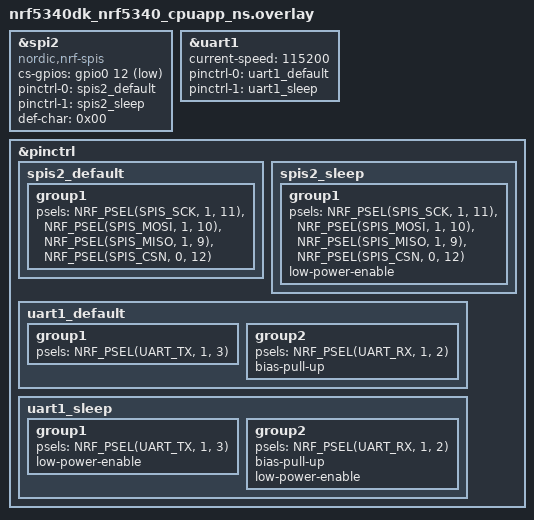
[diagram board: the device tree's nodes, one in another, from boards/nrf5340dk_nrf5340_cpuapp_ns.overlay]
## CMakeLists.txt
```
# SPDX-License-Identifier: Apache-2.0

cmake_minimum_required(VERSION 3.20.0)

# Ensure TFLM is visible to Zephyr even though it is not in west manifest.
set(EXTRA_ZEPHYR_MODULES
    $ENV{ZEPHYR_BASE}/modules/tflite-micro
)


find_package(Zephyr REQUIRED HINTS $ENV{ZEPHYR_BASE})
project(ecg_classifier)

# 添加源文件
target_sources(app PRIVATE
    src/main.c
    src/uart_sample_rx.c
    src/spi_comm.c
    src/ecg_buffer.c
    src/ecg_processing.c
    src/ble_output.c
)

if(NOT CONFIG_ECG_RAW_BLE_MODE)
    target_sources(app PRIVATE
        src/feature_extraction.c
        src/models/model_runtime.c
        src/models/model_backend_fnn_gboost_float.cc
        src/models/model_backend_fnn_float.cc
        src/models/model_backend_fnn_bagging_float.cc
        src/models/model_backend_fnn_gboost_int8.cc
        src/models/model_backend_fnn_bagging_int8.cc
        src/models/model_backend_fnn_int8.cc
        src/models/model_backend_binary_classic.c
        src/models/model_backend_binary_int8.c
        src/models/fnn_gboost_model_data.c
        src/models/fnn_float_model_data.c
        src/models/fnn_bagging_float_model_data.c
        src/models/fnn_gboost_int8_model_data.c
        src/models/fnn_int8_model_data.c
        src/models/fnn_bagging_int8_model_data.c
        fyp_integrate_int8/model_int8_params.c
        fyp_integrate_int8/utils_int8.c
        fyp_integrate/func.c
        fyp_integrate/model_globals.c
        fyp_integrate/1knn.c
        fyp_integrate/2dtree.c
        fyp_integrate/3svm.c
        fyp_integrate/4Bayes.c
        fyp_integrate/5lda.c
        fyp_integrate/7e_dtree.c
        fyp_integrate/8g_dtree.c
        fyp_integrate/11mix1.c
        fyp_integrate/12mix2.c
        fyp_integrate/13mix3.c
        src/online_moments.c
    )
endif()

# 添加头文件路径
target_include_directories(app PRIVATE include)
```

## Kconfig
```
#
# Application Kconfig
#

source "Kconfig.zephyr"

menu "ECG Application"

config ECG_RAW_BLE_MODE
	bool "Raw BLE passthrough mode"
	default n
	help
	  When enabled, all received ECG data is sent directly via BLE
	  without any feature extraction or model inference processing.
	  This is used for data collection and testing purposes.

config ECG_RAW_BLE_BASELINE
	bool "Raw BLE baseline power test mode"
	depends on ECG_RAW_BLE_MODE
	default n
	help
	  Enables baseline power test behavior for raw BLE mode:
	  - Keep UART print output enabled for controlled comparison
	  - Keep BLE send path active even when central is disconnected
	  This mode is intended only for power characterization.

endmenu
```

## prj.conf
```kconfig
# Copyright (c) 2018 Nordic Semiconductor
#
# SPDX-License-Identifier: LicenseRef-Nordic-5-Clause
#

# Enable the UART driver
CONFIG_UART_ASYNC_API=y
CONFIG_NRFX_UARTE0=y
CONFIG_NRFX_UARTE1=y
CONFIG_SERIAL=y

CONFIG_GPIO=y

# Make sure printk is printing to the UART console
CONFIG_CONSOLE=y
CONFIG_UART_CONSOLE=y

CONFIG_HEAP_MEM_POOL_SIZE=4096

CONFIG_BT=y
CONFIG_BT_PERIPHERAL=y
CONFIG_BT_DEVICE_NAME="Nordic_UART_Service"
CONFIG_BT_MAX_CONN=1
CONFIG_BT_MAX_PAIRED=1

# Enable the NUS service
CONFIG_BT_NUS=y

# Increase BLE throughput to support larger NUS packets
CONFIG_BT_L2CAP_TX_MTU=247
CONFIG_BT_BUF_ACL_TX_SIZE=251
CONFIG_BT_BUF_ACL_RX_SIZE=251
CONFIG_BT_CTLR_DATA_LENGTH_MAX=251

# Enable bonding
CONFIG_BT_SETTINGS=y
CONFIG_FLASH=y
CONFIG_FLASH_PAGE_LAYOUT=y
CONFIG_FLASH_MAP=y

# Enable DK LED and Buttons library
CONFIG_DK_LIBRARY=y

CONFIG_SYSTEM_WORKQUEUE_STACK_SIZE=4096
# Config logger
CONFIG_LOG=y
CONFIG_USE_SEGGER_RTT=y
CONFIG_LOG_BACKEND_RTT=y
CONFIG_LOG_BACKEND_UART=n
CONFIG_LOG_PRINTK=n

#Enable debugger
CONFIG_DEBUG_OPTIMIZATIONS=y
CONFIG_ASSERT=y
CONFIG_DEBUG_INFO=y
CONFIG_DEBUG_THREAD_INFO=y

# SPI configuration
CONFIG_SPI=y
CONFIG_SPI_SLAVE=y
CONFIG_SPI_LOG_LEVEL_INF=y
CONFIG_SPI_ASYNC=y

# Memory configuration
CONFIG_HEAP_MEM_POOL_SIZE=8192
CONFIG_MAIN_STACK_SIZE=4096

# Math library support
CONFIG_NEWLIB_LIBC=y
CONFIG_CPP=y
CONFIG_STD_CPP17=y
CONFIG_TENSORFLOW_LITE_MICRO=y

# printk float support
CONFIG_CBPRINTF_COMPLETE=y
CONFIG_CBPRINTF_FP_SUPPORT=y
# CONFIG_NEWLIB_LIBC_FLOAT_PRINTF=y
# CONFIG_NEWLIB_LIBC_FLOAT_SCANF=y
CONFIG_FPU=y

# Enable floating point support
# CONFIG_CBPRINTF_FP_SUPPORT=y
```

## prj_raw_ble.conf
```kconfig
#
# prj_raw_ble.conf - Raw BLE passthrough mode
# 所有ECG数据直接通过BLE转发，不做特征提取和推理
# 关闭所有串口打印，最大化BLE吞吐
#

# Enable raw BLE passthrough mode
CONFIG_ECG_RAW_BLE_MODE=y
CONFIG_ECG_RAW_BLE_BASELINE=y

# UART driver (for ECG data reception only)
CONFIG_UART_ASYNC_API=y
CONFIG_NRFX_UARTE0=y
CONFIG_NRFX_UARTE1=y
CONFIG_SERIAL=y

CONFIG_GPIO=y

# Enable UART console/printk output (match normal test visibility)
CONFIG_CONSOLE=y
CONFIG_UART_CONSOLE=y
CONFIG_PRINTK=y

# Enable logging on UART for baseline comparison
CONFIG_LOG=y
CONFIG_USE_SEGGER_RTT=n
CONFIG_LOG_BACKEND_RTT=n
CONFIG_LOG_BACKEND_UART=y
CONFIG_LOG_PRINTK=n

# Keep debug/assert aligned with normal logic test style
CONFIG_ASSERT=y
CONFIG_DEBUG_OPTIMIZATIONS=y
CONFIG_DEBUG_INFO=y
CONFIG_DEBUG_THREAD_INFO=y

# BLE configuration
CONFIG_BT=y
CONFIG_BT_PERIPHERAL=y
CONFIG_BT_DEVICE_NAME="Nordic_UART_Service"
CONFIG_BT_MAX_CONN=1
CONFIG_BT_MAX_PAIRED=1

CONFIG_BT_NUS=y

# Throughput settings (match normal mode)
CONFIG_BT_L2CAP_TX_MTU=247
CONFIG_BT_BUF_ACL_TX_SIZE=251
CONFIG_BT_BUF_ACL_RX_SIZE=251
CONFIG_BT_CTLR_DATA_LENGTH_MAX=251
CONFIG_BT_CONN_TX_MAX=10

# Prefer shorter connection interval for faster NUS notifications
CONFIG_BT_GAP_AUTO_UPDATE_CONN_PARAMS=y
CONFIG_BT_PERIPHERAL_PREF_MIN_INT=6
CONFIG_BT_PERIPHERAL_PREF_MAX_INT=12
CONFIG_BT_PERIPHERAL_PREF_LATENCY=0
CONFIG_BT_PERIPHERAL_PREF_TIMEOUT=400

CONFIG_BT_SETTINGS=y
CONFIG_FLASH=y
CONFIG_FLASH_PAGE_LAYOUT=y
CONFIG_FLASH_MAP=y

CONFIG_DK_LIBRARY=y

CONFIG_HEAP_MEM_POOL_SIZE=8192
CONFIG_MAIN_STACK_SIZE=4096
CONFIG_SYSTEM_WORKQUEUE_STACK_SIZE=4096

# SPI configuration
CONFIG_SPI=y
CONFIG_SPI_SLAVE=y
CONFIG_SPI_ASYNC=y

# Math/libc (still needed for memcpy etc.)
CONFIG_NEWLIB_LIBC=y
CONFIG_FPU=y

# No C++ / TFLM needed in raw mode
CONFIG_CPP=n
```

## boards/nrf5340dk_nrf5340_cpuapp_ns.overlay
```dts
// To get started, press Ctrl+Space to bring up the completion menu and view the available nodes.

// You can also use the buttons in the sidebar to perform actions on nodes.
// Actions currently available include:

// * Enabling / disabling the node
// * Adding the bus to a bus
// * Removing the node
// * Connecting ADC channels

// For more help, browse the DeviceTree documentation at https://docs.zephyrproject.org/latest/guides/dts/index.html
// You can also visit the nRF DeviceTree extension documentation at https://docs.nordicsemi.com/bundle/nrf-connect-vscode/page/guides/ncs_configure_app.html#devicetree-support-in-the-extension
/* Enable SPIS1 on nRF5340 DK */
&spi2 {
    compatible = "nordic,nrf-spis";   /* 改为从机模式 */
    status = "okay";

    /* CS = P0.12 (Active-low) */
    cs-gpios = <&gpio0 12 GPIO_ACTIVE_LOW>;

    pinctrl-0 = <&spis2_default>;
    pinctrl-1 = <&spis2_sleep>;
    pinctrl-names = "default", "sleep";
    def-char = < 0x00 >; /* SPIS 从机默认返回字符 */
};

&uart1 {
    status = "okay";
    current-speed = <115200>;
    pinctrl-0 = <&uart1_default>;
    pinctrl-1 = <&uart1_sleep>;
    pinctrl-names = "default", "sleep";
};

/* Pin control config */
&pinctrl {
    spis2_default: spis2_default {
        group1 {
            psels = 
                <NRF_PSEL(SPIS_SCK,  1, 11)>,   /* SCK  P1.11 */
                <NRF_PSEL(SPIS_MOSI, 1, 10)>,   /* MOSI P1.10 */
                <NRF_PSEL(SPIS_MISO, 1, 9)>,   /* MISO P1.09 */
                <NRF_PSEL(SPIS_CSN,  0, 12)>;  /* ★ 关键：CS */
        };
    };

    spis2_sleep: spis2_sleep {
        group1 {
            psels = 
                <NRF_PSEL(SPIS_SCK,  1, 11)>,   /* SCK  P1.11 */
                <NRF_PSEL(SPIS_MOSI, 1, 10)>,   /* MOSI P1.10 */
                <NRF_PSEL(SPIS_MISO, 1, 9)>,   /* MISO P1.09 */
                <NRF_PSEL(SPIS_CSN,  0, 12)>;  /* ★ 关键：CS */
            low-power-enable;
        };
    };

    uart1_default: uart1_default {
        group1 {
            psels = <NRF_PSEL(UART_TX, 1, 3)>;
        };

        group2 {
            psels = <NRF_PSEL(UART_RX, 1, 2)>;
            bias-pull-up;
        };
    };

    uart1_sleep: uart1_sleep {
        group1 {
            psels = <NRF_PSEL(UART_TX, 1, 3)>;
            low-power-enable;
        };

        group2 {
            psels = <NRF_PSEL(UART_RX, 1, 2)>;
            bias-pull-up;
            low-power-enable;
        };
    };
};
```

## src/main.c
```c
/**
 * @file main.c
 * @brief NRF5340 ECG应用主程序
 * 
 * 架构（异步快照版）：
 * UART ISR → ECG缓冲队列 → 主循环收集样本 → 快照 → k_work工作线程处理
 *   主循环：只负责收集，不做耗时计算，收满即快照+提交work+立即继续
 *   工作线程：process_window + 特征提取 + 模型推理 + (未来)BLE发送
 */

#include <zephyr/kernel.h>
#include <zephyr/logging/log.h>
#include <zephyr/sys/printk.h>
#include <errno.h>
#include <string.h>

#include "uart_sample_rx.h"
#include "ecg_buffer.h"
#include "ecg_processing.h"
#include "ble_output.h"

#if !IS_ENABLED(CONFIG_ECG_RAW_BLE_MODE)
#include "feature_extraction.h"
#include "models/model_runtime.h"
#endif

LOG_MODULE_REGISTER(app, LOG_LEVEL_INF);

/* ===== 配置常量 ===== */
#define ECG_FS              300
#define WINDOW_SEC          30
#define ECG_BUFFER_SIZE     200   /* 扩大缓冲区，覆盖快照memcpy期间ISR写入 */
#define BLE_QUEUE_SIZE      10
#define ENABLE_BLE_OUTPUT   0

/* ===== 主循环收集用对象 ===== */
static ecg_buffer_t ecg_buffer;

#if IS_ENABLED(CONFIG_ECG_RAW_BLE_MODE)
/* ===== Raw BLE passthrough: 仅需一个样本缓冲区 ===== */
static int16_t raw_buffer[BLE_OUTPUT_MAX_WINDOW_SAMPLES];
static uint32_t raw_buffer_pos;
static uint32_t raw_target_samples;
static uint32_t raw_windows_collected;
static uint32_t raw_windows_submitted;
static uint32_t raw_windows_skipped;

#else /* Normal processing mode */

/* 当前默认模型 */
#define ACTIVE_MODEL        ECG_MODEL_BIN_I8_SVM

static window_manager_t window_mgr;
static feature_extraction_t feature_eng;
static ecg_model_runtime_t model_runtime;

/* ===== 快照区：主循环写入，工作线程读取，信号量保护 ===== */
static feature_extraction_t snap_feature_eng;
static window_integrity_t   snap_integrity;
static uint16_t             snap_file_id;
static K_SEM_DEFINE(snap_sem, 1, 1);  /* 1=快照区空闲, 0=工作线程占用 */

/* ===== 工作队列 ===== */
static struct k_work process_work;
static uint32_t snap_timestamp_ms;     /* 快照时刻 */
static uint32_t windows_collected;     /* 主循环已收集窗口计数 */
static uint32_t windows_processed;     /* 工作线程已处理窗口计数 */
static uint32_t windows_skipped;       /* 快照区忙导致跳过的窗口计数 */

/**
 * @brief 工作线程处理函数
 * 
 * 在系统工作队列线程中执行，不阻塞主循环。
 * 流程：process_window → 特征提取 → 模型推理 → 打印结果 → 释放快照区  
 */
static void process_work_handler(struct k_work *work)
{
    ARG_UNUSED(work);

    uint32_t work_t0 = k_uptime_get_32();

    printk("\n[WORK] === Processing snapshot file=%u (collected=%u) ===\n",
           snap_file_id, windows_collected);

    /* 1) 执行 process_window（耗时 ~154ms） */
    uint32_t pw_t0 = k_uptime_get_32();
    process_window(&snap_feature_eng);
    uint32_t pw_t1 = k_uptime_get_32();
    snap_feature_eng.last_extract_time_ms = (pw_t1 - pw_t0);

    if (!snap_feature_eng.ready) {
        printk("[WORK] process_window failed for file=%u\n", snap_file_id);
        windows_processed++;
        k_sem_give(&snap_sem);
        return;
    }

    /* 2) 提取特征 */
    double features[6];
    feature_extraction_get(features, &snap_feature_eng);

    printk("[WORK] Feature extraction time: %u ms\n", snap_feature_eng.last_extract_time_ms);
    printk("[WORK] Window integrity: %u%% (%u/%u samples)\n",
           snap_integrity.integrity_percent,
           snap_integrity.received_samples,
           snap_integrity.expected_samples);
    printk("[WORK] Kurtosis: [%.4f, %.4f, %.4f]\n",
           features[0], features[1], features[2]);
    printk("[WORK] Skewness: [%.4f, %.4f, %.4f]\n",
           features[3], features[4], features[5]);

    /* 3) 模型推理 */
    ecg_model_result_t infer_out = {0};
    uint32_t inf_t0 = k_uptime_get_32();
    int ret = ecg_model_runtime_infer(&model_runtime, features, &infer_out);
    uint32_t inf_t1 = k_uptime_get_32();

    printk("[WORK] Inference time: %u ms\n", (inf_t1 - inf_t0));

    if (ret == 0) {
        printk("[WORK] Inference: model=%s label=%d score=%.5f\n",
               ecg_model_runtime_name(model_runtime.active_model),
               infer_out.label, (double)infer_out.score);
    } else {
        printk("[WORK] Inference failed: %d\n", ret);
    }

    /* 4) 结果判断 + 备份数据可用性验证 */
    if (ret == 0 && snap_integrity.is_valid && infer_out.label == 1) {
        printk("[WORK] >>> VALID: file=%u label=1, backup %u samples ready for BLE <<<\n",
               snap_file_id, snap_feature_eng.buffer_pos);

#if ENABLE_BLE_OUTPUT
        int ble_ret = ble_output_submit_window(
            snap_file_id,
            snap_feature_eng.buffer,
            snap_feature_eng.buffer_pos,
            ECG_FS,
            (uint8_t)snap_integrity.integrity_percent,
            infer_out.label
        );

        if (ble_ret == 0) {
            printk("[WORK] BLE submit OK: file=%u samples=%u connected=%d\n",
                   snap_file_id,
                   snap_feature_eng.buffer_pos,
                   ble_output_is_connected() ? 1 : 0);
        } else if (ble_ret == -EBUSY) {
            printk("[WORK] BLE submit BUSY: previous window still sending, file=%u skipped\n",
                   snap_file_id);
        } else {
            printk("[WORK] BLE submit failed: %d (file=%u)\n", ble_ret, snap_file_id);
        }
#endif
    } else {
        printk("[WORK] Window not sent: integrity=%u%% label=%d ret=%d\n",
               snap_integrity.integrity_percent,
               (ret == 0) ? infer_out.label : -1, ret);
    }

    uint32_t work_t1 = k_uptime_get_32();
    printk("[WORK] Total work time: %u ms (snap_delay=%u ms)\n",
           (work_t1 - work_t0), (work_t0 - snap_timestamp_ms));

    windows_processed++;
    printk("[WORK] Stats: collected=%u processed=%u skipped=%u\n",
           windows_collected, windows_processed, windows_skipped);

    /* 5) 释放快照区，主循环可以写入下一个快照 */
    k_sem_give(&snap_sem);
}

#endif /* !CONFIG_ECG_RAW_BLE_MODE */

/**
 * @brief 主程序
 */
int main(void)
{
    printk("=== NRF5340 ECG Application Start ===\n");

    int ret = ecg_buffer_init(&ecg_buffer, ECG_BUFFER_SIZE);
    if (ret != 0) {
        printk("Failed to init ECG buffer: %d\n", ret);
        return ret;
    }

    ret = uart_sample_rx_init_async(&ecg_buffer);
    if (ret != 0) {
        printk("Failed to init UART RX: %d\n", ret);
        return ret;
    }

#if IS_ENABLED(CONFIG_ECG_RAW_BLE_MODE)
    /* ===== Raw BLE passthrough mode ===== */
    printk("Mode: RAW BLE PASSTHROUGH (no processing)\n");

    ret = ble_output_init(BLE_QUEUE_SIZE);
    if (ret != 0) {
        printk("Failed to init BLE output: %d\n", ret);
        return ret;
    }

    ret = ble_output_start();
    if (ret != 0) {
        printk("Failed to start BLE stack: %d\n", ret);
        return ret;
    }

    printk("BLE ready, waiting for connection...\n");

    raw_windows_collected = 0;
    raw_windows_submitted = 0;
    raw_windows_skipped = 0;

    ecg_sample_t sample;
    bool window_active = false;
    uint16_t current_file_id = 0;

    while (1) {
        uart_window_header_t header;
        if (uart_sample_rx_try_get_window_header(&header)) {
            if (window_active) {
                printk("[RAW] Header file=%u IGNORED (busy file=%u)\n",
                       header.file_id, current_file_id);
            } else {
                if (header.sample_count == 0 ||
                    header.sample_count > BLE_OUTPUT_MAX_WINDOW_SAMPLES) {
                    printk("[RAW] Invalid sample count: %u\n", header.sample_count);
                    continue;
                }
                raw_target_samples = header.sample_count;
                raw_buffer_pos = 0;
                current_file_id = header.file_id;
                window_active = true;
                printk("[RAW] Header file=%u samples=%u\n",
                       header.file_id, header.sample_count);
            }
        }

        if (!window_active) {
            k_sleep(K_USEC(100));
            continue;
        }

        int pop_ret = ecg_buffer_pop(&ecg_buffer, &sample);
        if (pop_ret == -ENODATA) {
            k_sleep(K_USEC(100));
            continue;
        }

        if (raw_buffer_pos < raw_target_samples) {
            raw_buffer[raw_buffer_pos++] = sample.ecg_data;
        }

        if (raw_buffer_pos >= raw_target_samples) {
            /* 窗口收满，直接提交 BLE 发送 */
             uint32_t raw_t0 = k_uptime_get_32();
             raw_windows_collected++;

             if (IS_ENABLED(CONFIG_ECG_RAW_BLE_BASELINE)) {
              printk("\n[WORK] === Processing snapshot file=%u (collected=%u) ===\n",
                  current_file_id, raw_windows_collected);
              printk("[WORK] Feature extraction time: 0 ms\n");
              printk("[WORK] Window integrity: 100%% (%u/%u samples)\n",
                  raw_buffer_pos, raw_target_samples);
              printk("[WORK] Kurtosis: [0.0000, 0.0000, 0.0000]\n");
              printk("[WORK] Skewness: [0.0000, 0.0000, 0.0000]\n");
              printk("[WORK] Inference time: 0 ms\n");
              printk("[WORK] Inference: model=RAW_BASELINE label=1 score=0.00000\n");
             }

            printk("[RAW] Window done: file=%u samples=%u, submitting BLE...\n",
                   current_file_id, raw_buffer_pos);

            int ble_ret = ble_output_submit_window(
                current_file_id,
                raw_buffer,
                raw_buffer_pos,
                ECG_FS,
                100,    /* raw模式下integrity固定100% */
                0       /* raw模式下model_output=0(未推理) */
            );

            if (ble_ret == 0) {
                raw_windows_submitted++;
                printk("[RAW] BLE submit OK: file=%u\n", current_file_id);
            } else if (ble_ret == -EBUSY) {
                raw_windows_skipped++;
                printk("[RAW] BLE BUSY: file=%u skipped\n", current_file_id);
            } else {
                printk("[RAW] BLE submit failed: %d\n", ble_ret);
            }

            if (IS_ENABLED(CONFIG_ECG_RAW_BLE_BASELINE)) {
                uint32_t raw_t1 = k_uptime_get_32();
                printk("[WORK] Total work time: %u ms\n", (raw_t1 - raw_t0));
                printk("[WORK] Stats: collected=%u processed=%u skipped=%u\n",
                       raw_windows_collected,
                       raw_windows_submitted,
                       raw_windows_skipped);
            }

            window_active = false;
        }
    }

#else /* Normal processing mode */

    printk("\n\n========================================\n");
    printk("   NRF5340 ECG Async Snapshot Demo\n");
    printk("   Sam: %u Hz, Window: %u sec\n", ECG_FS, WINDOW_SEC);
    printk("   ECG Buffer: %u slots\n", ECG_BUFFER_SIZE);
    printk("========================================\n\n");

    window_manager_init(&window_mgr, ECG_FS, WINDOW_SEC);
    feature_extraction_init(&feature_eng, ECG_FS, WINDOW_SEC);

    ret = ecg_model_runtime_init(&model_runtime, ACTIVE_MODEL);
    if (ret != 0) {
        printk("Failed to init model runtime: %d\n", ret);
        return ret;
    }
    printk("Model: %s\n", ecg_model_runtime_name(model_runtime.active_model));

#if ENABLE_BLE_OUTPUT
    ret = ble_output_init(BLE_QUEUE_SIZE);
    if (ret != 0) {
        printk("Failed to init BLE output: %d\n", ret);
        return ret;
    }

    ret = ble_output_start();
    if (ret != 0) {
        printk("Failed to start BLE stack: %d\n", ret);
        return ret;
    }

    printk("BLE stream ready, waiting for central connection...\n");
#endif

    /* 初始化工作项 */
    k_work_init(&process_work, process_work_handler);
    windows_collected = 0;
    windows_processed = 0;
    windows_skipped = 0;

    printk("All modules initialized. Starting collection loop...\n");

    ecg_sample_t sample;
    window_integrity_t integrity;
    bool window_active = false;
    uint16_t current_file_id = 0;

    while (1) {
        /* ---- 检查新头帧（仅在非收集状态下接受） ---- */
        uart_window_header_t header;
        if (uart_sample_rx_try_get_window_header(&header)) {
            if (window_active) {
                /* 正在收集中，忽略此头帧（ISR数据继续入buffer会被下轮消费掉） */
                printk("[MAIN] Header for file=%u IGNORED (busy collecting file=%u, pos=%u/%u)\n",
                       header.file_id, current_file_id,
                       feature_eng.buffer_pos, feature_eng.target_samples);
            } else {
                ret = feature_extraction_set_target_samples(&feature_eng, header.sample_count);
                if (ret != 0) {
                    printk("[MAIN] Invalid sample count from header: %u\n", header.sample_count);
                    continue;
                }

                ret = window_manager_set_expected_samples(&window_mgr, header.sample_count);
                if (ret != 0) {
                    printk("[MAIN] Invalid window sample count: %u\n", header.sample_count);
                    continue;
                }

                feature_extraction_reset(&feature_eng);
                window_manager_reset(&window_mgr);

                current_file_id = header.file_id;
                window_active = true;

                printk("\n[MAIN] >>> Header file=%u samples=%u <<<\n",
                       header.file_id, header.sample_count);
            }
        }

        if (!window_active) {
            k_sleep(K_USEC(100));
            continue;
        }

        /* ---- 逐样本弹出并推入特征收集器 ---- */
        int pop_ret = ecg_buffer_pop(&ecg_buffer, &sample);
        if (pop_ret == -ENODATA) {
            k_sleep(K_USEC(100));
            continue;
        }

        bool feature_done = feature_extraction_push(&feature_eng, sample.ecg_data);
        bool window_done = window_manager_push(&window_mgr, sample.seq_num, &integrity);

        if (!feature_done || !window_done) {
            continue;
        }

        /* ---- 窗口收集完毕：快照 + 提交工作 ---- */
        uint32_t snap_t0 = k_uptime_get_32();
        windows_collected++;

        /* 尝试获取快照区锁（非阻塞） */
        if (k_sem_take(&snap_sem, K_NO_WAIT) != 0) {
            /* 上一个快照还在处理中，跳过本窗口 */
            windows_skipped++;
            printk("[MAIN] !!! SKIP file=%u: work thread busy (skipped=%u) !!!\n",
                   current_file_id, windows_skipped);
            feature_extraction_reset(&feature_eng);
            window_manager_reset(&window_mgr);
            window_active = false;
            continue;
        }

        /* 快照：memcpy feature_eng → snap_feature_eng（~18KB for 9000 samples） */
        memcpy(&snap_feature_eng, &feature_eng, sizeof(feature_extraction_t));
        snap_integrity = integrity;
        snap_file_id = current_file_id;
        snap_timestamp_ms = snap_t0;

        uint32_t snap_t1 = k_uptime_get_32();
        printk("[MAIN] Snapshot file=%u done in %u ms (buffer_pos=%u)\n",
               current_file_id, (snap_t1 - snap_t0), feature_eng.buffer_pos);

        /* 立即重置收集器，准备下一窗口 */
        feature_extraction_reset(&feature_eng);
        window_manager_reset(&window_mgr);
        window_active = false;

        /* 提交到系统工作队列（不阻塞主循环） */
        k_work_submit(&process_work);

        //printk("[MAIN] Work submitted, resuming collection...\n");
    }

#endif /* CONFIG_ECG_RAW_BLE_MODE */

    return 0;
}
```

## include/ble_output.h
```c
/**
 * @file ble_output.h
 * @brief 蓝牙输出接口（预留）
 * 
 * 功能：
 * - 结果队列管理
 * - 蓝牙发送接口
 * - 数据格式转换
 */

#ifndef BLE_OUTPUT_H
#define BLE_OUTPUT_H

#include <stdint.h>
#include <stdbool.h>
#include "ecg_processing.h"

#define BLE_STREAM_PKT_VERSION         1
#define BLE_STREAM_PKT_START           0xA1
#define BLE_STREAM_PKT_DATA            0xA2
#define BLE_STREAM_PKT_END             0xA3

#define BLE_OUTPUT_MAX_WINDOW_SAMPLES  12000
#define BLE_STREAM_CHUNK_SAMPLES       6

/**
 * @brief 蓝牙消息体
 */
typedef struct {
    uint32_t timestamp_ms;      /* 消息时间戳 */
    
    uint8_t msg_type;           /* 消息类型: 1=诊断结果, 2=警告, 3=统计 */
    uint8_t status;             /* 状态码 */
    
    /* 数据包 - 可根据msg_type灵活解释 */
    union {
        struct {
            /* 诊断结果 */
            float kurtosis[3];
            float skewness[3];
            int32_t model_output;
            uint8_t window_integrity_percent;
        } diagnosis;
        
        struct {
            /* 数据质量警告 */
            uint8_t loss_percent;
            uint32_t missing_count;
            uint8_t severity;  /* 0=低, 1=中, 2=高 */
        } warning;
        
        struct {
            /* 统计信息 */
            uint32_t total_frames;
            uint32_t total_lost;
            uint32_t windows_valid;
            uint32_t windows_invalid;
        } stats;
    } data;
} ble_message_t;

/**
 * @brief 初始化蓝牙队列
 * @param queue_size 队列容量
 * @return 0成功
 */
int ble_output_init(uint32_t queue_size);

/**
 * @brief 清除蓝牙队列
 */
void ble_output_reset(void);

/**
 * @brief 销毁蓝牙队列（释放资源）
 */
void ble_output_deinit(void);

/**
 * @brief 将ECG处理结果加入发送队列
 * @param result ECG处理结果
 * @return 0成功，<0失败
 */
int ble_output_queue_result(const ecg_result_t *result);

/**
 * @brief 将诊断警告加入发送队列
 * @param loss_percent 丢帧率
 * @param severity 严重级别 (0/1/2)
 * @return 0成功
 */
int ble_output_queue_warning(uint8_t loss_percent, uint8_t severity);

/**
 * @brief 从队列中取出消息（待发送）
 * @param msg 输出消息指针
 * @return 0成功，-ENODATA队列空
 */
int ble_output_dequeue_message(ble_message_t *msg);

/**
 * @brief 获取队列统计
 */
typedef struct {
    uint32_t queued_count;      /* 待发送消息数 */
    uint32_t total_sent;        /* 已发送总数（仅当BLE已集成时） */
    uint32_t send_errors;       /* 发送错误数 */
} ble_stats_t;

ble_stats_t ble_output_get_stats(void);

/**
 * @brief 实际蓝牙发送函数接口
 * 
 * 这个函数需要用户根据蓝牙栈自行实现（如NRF5 SDK的GATT）
 * 作为回调注册给ble_output模块
 */
typedef int (*ble_send_callback_t)(const uint8_t *data, uint16_t length);

/**
 * @brief 注册蓝牙发送回调
 * 
 * 使用示例：
 * @code
 * int my_ble_send(const uint8_t *data, uint16_t len) {
 *     // 通过NRF SDK的notify/indicate机制发送
 *     return ble_gatt_notify(data, len);
 * }
 * 
 * ble_output_register_send_callback(my_ble_send);
 * @endcode
 */
void ble_output_register_send_callback(ble_send_callback_t callback);

/**
 * @brief 启动后台蓝牙发送线程（可选）
 * 
 * 如果启用，蓝牙输出将自动从队列中取消息并发送
 * 否则需要应用层定期调用 ble_output_send_pending()
 */
int ble_output_start_background_sender(void);

/**
 * @brief 手动发送待发送的消息（如不使用后台线程）
 * @return 实际发送的消息数
 */
uint32_t ble_output_send_pending(void);

/**
 * @brief 初始化并启动 BLE NUS 发送链路
 *
 * 启动流程：
 * 1) bt_enable
 * 2) bt_nus_init
 * 3) 开始广播
 * 4) 启动窗口发送线程
 *
 * @return 0 成功, <0 失败
 */
int ble_output_start(void);

/**
 * @brief 查询当前是否有 BLE 连接
 */
bool ble_output_is_connected(void);

/**
 * @brief 提交一个有效窗口到 BLE 发送槽（异步发送）
 *
 * 发送协议:
 * - START: [type, ver, file_id(2), sample_count(4), fs_hz(2), integrity(1), label(1)]
 * - DATA:  [type, ver, file_id(2), start_idx(2), count(1), samples(count*2)]
 * - END:   [type, ver, file_id(2), sent_count(2), integrity(1), label(1)]
 *
 * @param file_id 窗口文件编号
 * @param samples 窗口样本数组（int16 LE）
 * @param sample_count 样本个数
 * @param fs_hz 采样率
 * @param integrity_percent 完整性百分比
 * @param model_output 模型标签（当前用 0/1）
 * @return 0 成功, -EBUSY 发送槽忙, <0 其他失败
 */
int ble_output_submit_window(uint16_t file_id,
                             const int16_t *samples,
                             uint32_t sample_count,
                             uint16_t fs_hz,
                             uint8_t integrity_percent,
                             int32_t model_output);

#endif /* BLE_OUTPUT_H */
```

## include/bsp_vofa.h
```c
#ifndef VOFA_H
#define VOFA_H


#ifdef __cplusplus
extern "C" {
#endif
#define NOFCHANEL 10
	
typedef union
{
    float fdata[NOFCHANEL];
    unsigned char cdata[NOFCHANEL*4+4];
}transform;	
int TO_Vofa_DATA(void);

#ifdef __cplusplus
}
#endif
#endif
```

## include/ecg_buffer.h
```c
/**
 * @file ecg_buffer.h
 * @brief ECG数据FIFO环形缓冲队列管理
 * 
 * 功能：
 * - 脱耦SPI中断处理与主处理逻辑
 * - 防止主机快速发送导致丢帧
 * - 线程安全操作（K_SPINLOCK保护）
 */

#ifndef ECG_BUFFER_H
#define ECG_BUFFER_H

#include <stdint.h>
#include <stdbool.h>
/**
 * @brief ECG样本数据单元
 * 注意：这是处理后的数据
 */
typedef struct {
    uint32_t seq_num;       /* 序列号，用于检测丢帧 */
    int16_t  ecg_data;      /* ECG原始样本值 */
    uint32_t timestamp_ms;  /* 接收时间戳 */
    uint8_t  status;        /* 帧状态标志 (0=正常, 1=重复, 2=乱序等) */
} ecg_sample_t;

/**
 * @brief ECG缓冲队列
 */
typedef struct {
    ecg_sample_t *buffer;
    uint32_t size;          /* 缓冲区大小 */
    uint32_t head;          /* 写指针（生产者） */
    uint32_t tail;          /* 读指针（消费者） */
    uint32_t count;         /* 当前队列中元素数 */
    
    /* 统计信息 */
    uint32_t total_received;    /* 总接收帧数 */
    uint32_t total_lost;        /* 总丢失帧数 */
    uint32_t last_seq;          /* 上一个序列号 */
} ecg_buffer_t;

/**
 * @brief 初始化ECG缓冲队列
 * @param buf 缓冲队列结构体指针
 * @param size 队列容量（推荐 >= (ECG_FS * 30 / 4)，即单个30s窗口的数据量）
 * @return 0成功，<0失败
 */
int ecg_buffer_init(ecg_buffer_t *buf, uint32_t size);

/**
 * @brief 清除缓冲队列（重置统计但保留内存）
 */
void ecg_buffer_reset(ecg_buffer_t *buf);

/**
 * @brief 销毁缓冲队列（释放内存）
 */
void ecg_buffer_deinit(ecg_buffer_t *buf);

/**
 * @brief 将ECG样本写入队列（由SPI异步回调调用）
 * @param buf 缓冲队列
 * @param sample ECG样本指针
 * @return 0成功，-ENOBUFS队列满（丢帧警告）
 */
int ecg_buffer_push(ecg_buffer_t *buf, const ecg_sample_t *sample);

/**
 * @brief 从队列读取一个ECG样本（由主处理线程调用）
 * @param buf 缓冲队列
 * @param sample 输出样本指针
 * @return 0成功，-ENODATA队列空
 */
int ecg_buffer_pop(ecg_buffer_t *buf, ecg_sample_t *sample);

/**
 * @brief 查询队列是否为空
 */
bool ecg_buffer_is_empty(const ecg_buffer_t *buf);

/**
 * @brief 查询队列是否满
 */
bool ecg_buffer_is_full(const ecg_buffer_t *buf);

/**
 * @brief 获取当前队列中的元素数
 */
uint32_t ecg_buffer_count(const ecg_buffer_t *buf);

/**
 * @brief 获取缓冲区使用率（百分比）
 */
uint8_t ecg_buffer_usage_percent(const ecg_buffer_t *buf);

/**
 * @brief 获取统计信息
 */
typedef struct {
    uint32_t total_received;
    uint32_t total_lost;
    uint8_t loss_percent;
} ecg_buffer_stats_t;

void ecg_buffer_get_stats(const ecg_buffer_t *buf, ecg_buffer_stats_t *stats);

#endif /* ECG_BUFFER_H */
```

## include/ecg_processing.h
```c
/**
 * @file ecg_processing.h
 * @brief ECG数据处理流程管理
 * 
 * 功能：
 * - 30秒窗口完整性判断
 * - 数据处理流程协调
 * - 蓝牙输出队列预留
 */

#ifndef ECG_PROCESSING_H
#define ECG_PROCESSING_H

#include <stdint.h>
#include <stdbool.h>

/**
 * @brief 30秒窗口的完整性信息
 */
typedef struct {
    uint32_t expected_samples;      /* 期望样本数 */
    uint32_t received_samples;      /* 实际接收样本数 */
    uint32_t missing_samples;       /* 缺失样本数 */
    uint32_t seq_gaps;              /* 序列号中断次数 */
    uint32_t integrity_percent;     /* 完整性百分比 (0-100) */
    bool is_valid;                  /* 是否有效 (>=95%) */
    uint32_t window_start_time_ms;  /* 窗口开始时间 */
    uint32_t window_end_time_ms;    /* 窗口结束时间 */
    uint32_t window_duration_ms;    /* 实际持续时间 */
} window_integrity_t;

/**
 * @brief ECG处理结果（待发送的数据）
 */
typedef struct {
    uint32_t timestamp_ms;          /* 结果生成时间 */
    
    /* 特征 */
    double kurtosis[3];             /* 三段峰度 */
    double skewness[3];             /* 三段偏度 */
    
    /* 完整性检查 */
    window_integrity_t integrity;   /* 窗口完整性 */
    
    /* 推理结果（保留） */
    int32_t model_output;           /* 模型输出 */
    float model_confidence;         /* 置信度 */
    
    /* 状态标志 */
    uint8_t status;                 /* 0=OK, 1=丢帧警告, 2=质量不足 */
} ecg_result_t;

/**
 * @brief 30秒窗口管理器
 */
typedef struct {
    /* 配置 */
    uint32_t fs;                    /* 采样率 Hz */
    uint32_t window_sec;            /* 窗口长度 秒 */
    uint32_t expected_samples;      /* 期望样本数 = fs * window_sec */
    
    /* 状态 */
    uint32_t sample_count;          /* 当前窗口已处理样本数 */
    uint32_t seq_last;              /* 上一个序列号 */
    uint32_t seq_gaps;              /* 序列号中断检测 */
    uint32_t window_start_time_ms;  /* 窗口开始时间戳 */
    
    /* 统计 */
    uint32_t windows_completed;     /* 完成窗口数 */
    uint32_t windows_invalid;       /* 无效窗口数 */
} window_manager_t;

/**
 * @brief 初始化窗口管理器
 * @param mgr 窗口管理器指针
 * @param fs 采样率（Hz）
 * @param window_sec 窗口长度（秒）
 */
void window_manager_init(window_manager_t *mgr, uint32_t fs, uint32_t window_sec);

/**
 * @brief 更新当前窗口期望样本数（用于动态窗口）
 * @param mgr 窗口管理器
 * @param expected_samples 该窗口应接收样本数
 * @return 0成功，<0失败
 */
int window_manager_set_expected_samples(window_manager_t *mgr, uint32_t expected_samples);

/**
 * @brief 处理一个ECG样本，返回是否完成了一个窗口
 * @param mgr 窗口管理器
 * @param seq_num 序列号
 * @param integrity 输出：完整性信息（仅当返回true时有效）
 * @return true=完成一个窗口, false=继续积累
 */
bool window_manager_push(window_manager_t *mgr, uint32_t seq_num, 
                         window_integrity_t *integrity);

/**
 * @brief 重置窗口（开始新的30秒周期）
 */
void window_manager_reset(window_manager_t *mgr);

/**
 * @brief 获取当前窗口的完整性信息（不重置）
 */
void window_manager_get_integrity(const window_manager_t *mgr, 
                                   window_integrity_t *integrity);

/**
 * @brief 获取窗口管理器的统计信息
 */
typedef struct {
    uint32_t windows_completed;
    uint32_t windows_invalid;
    float validity_percent;
} window_stats_t;

void window_manager_get_stats(const window_manager_t *mgr, window_stats_t *stats);

#endif /* ECG_PROCESSING_H */
```

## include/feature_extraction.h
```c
/* feature_extraction.h */

/* feature_extraction.h */

#pragma once
#include <stdint.h>
#include <stdbool.h>
#include "online_moments.h"

#define FEATURE_EXTRACTION_MAX_SAMPLES 12000

typedef struct {
    /* ==== configuration (constant) ==== */
    uint32_t fs;
    uint32_t window_sec;
    uint32_t target_samples;

    /* ==== runtime state ==== */
    /* 三段统计器 */
    online_moments_t seg1;
    online_moments_t seg2;
    online_moments_t seg3;

    /* 缓冲区存储12000样本 */
    int16_t buffer[FEATURE_EXTRACTION_MAX_SAMPLES];
    uint32_t buffer_pos;
    uint32_t last_extract_time_ms;

    bool ready;  /* 全部30秒是否处理完毕 */
} feature_extraction_t;

void feature_extraction_init(feature_extraction_t *e, uint32_t fs, uint32_t window_sec);
int feature_extraction_set_target_samples(feature_extraction_t *e, uint32_t target_samples);
bool feature_extraction_push(feature_extraction_t *e, int16_t raw_sample);
void feature_extraction_get(double out[6], feature_extraction_t *e);
void feature_extraction_reset(feature_extraction_t *e);
void process_window(feature_extraction_t *e);
```

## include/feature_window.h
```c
#pragma once
#include <stdbool.h>
#include <stdint.h>

typedef struct {
    int16_t *raw;
    uint32_t fs;
    uint32_t win_sec;
    uint32_t count;
    bool     ready;
} feature_window_t;

int  feature_window_init(feature_window_t *w,
                         uint32_t fs,
                         uint32_t win_sec);
bool feature_window_push(feature_window_t *w, int16_t sample);
void feature_window_reset(feature_window_t *w);

/* 预处理输出：返回降采样后数组和长度 */
int feature_window_preprocess(feature_window_t *w,
                              double **out,
                              uint32_t *out_len);
```

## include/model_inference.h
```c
/**
 * @file model_inference.h
 * @brief 决策树推理模块
 * 
 * 该模块使用训练好的决策树模型对提取的特征进行分类
 */

#ifndef MODEL_INFERENCE_H
#define MODEL_INFERENCE_H

#include <stdint.h>
#include "online_moments.h"

/**
 * @brief 决策树推理函数
 * @param features 输入特征向量(6维)
 * @return 分类结果: 0 或 1
 * 
 * 该函数会自动进行特征标准化，然后通过决策树进行推理
 */
int tree_predict(const feature_vector_t *features);

/**
 * @brief 标准化特征向量
 * @param features_raw 原始特征向量
 * @param features_normalized 标准化后的特征向量
 * 
 * 使用训练集的均值和标准差进行Z-score标准化
 */
void standardize_features(const feature_vector_t *features_raw, 
                         float *features_normalized);

#endif /* MODEL_INFERENCE_H */
```

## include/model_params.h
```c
/**
 * @file model_params.h
 * @brief 决策树模型参数定义
 * 
 * 该文件包含从MATLAB训练得到的决策树模型参数
 */

#ifndef MODEL_PARAMS_H
#define MODEL_PARAMS_H

#include <stdint.h>

#define N_FEATURES 6    // 特征数量: 3个峰度 + 3个偏度
#define N_NODES 43      // 决策树节点数量

/* 决策树结构参数 */
extern const int8_t  cut_feature[N_NODES];   // 每个节点的分裂特征索引
extern const float   cut_value[N_NODES];     // 每个节点的分裂阈值
extern const int16_t left_child[N_NODES];    // 左子节点索引
extern const int16_t right_child[N_NODES];   // 右子节点索引
extern const int8_t  is_branch[N_NODES];     // 是否为分支节点(1)或叶子节点(0)
extern const int8_t  node_class[N_NODES];    // 叶子节点的类别

/* 特征标准化参数 */
extern const float   mean_all[N_FEATURES];   // 训练集特征均值
extern const float   std_all[N_FEATURES];    // 训练集特征标准差

#endif /* MODEL_PARAMS_H */
```

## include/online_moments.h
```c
/* online_moments.h
 * Online (incremental) moments accumulator (Welford / Pébay extension)
 * Provides per-sample updates and functions to compute variance, skewness,
 * and excess kurtosis consistent with common sample-corrected formulas.
 *
 * Small footprint; use double for stability.
 */

#ifndef ONLINE_MOMENTS_H
#define ONLINE_MOMENTS_H

#include <stdint.h>

#ifdef __cplusplus
extern "C" {
#endif

typedef struct {
    uint32_t n;
    double mean;
    double M2;
    double M3;
    double M4;
} online_moments_t;

static inline void online_moments_init(online_moments_t *s)
{
    s->n = 0;
    s->mean = 0.0;
    s->M2 = 0.0;
    s->M3 = 0.0;
    s->M4 = 0.0;
}

void online_moments_update(online_moments_t *s, double x);

/* sample variance (unbiased, divided by n-1). Returns NAN when n<2 */
double online_moments_variance(const online_moments_t *s);

/* population skewness (MATLAB default): m3 / m2^(3/2). Returns NAN when n<3 */
double online_moments_skewness(const online_moments_t *s);

/* raw kurtosis (MATLAB default): m4 / m2^2 (NOT excess). Returns NAN when n<4 */
double online_moments_kurtosis_raw(const online_moments_t *s);

#ifdef __cplusplus
}
#endif

#endif /* ONLINE_MOMENTS_H */
```

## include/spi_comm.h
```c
#ifndef SPI_COMM_H
#define SPI_COMM_H

#include <stdint.h>
#include <stdbool.h>
#include "ecg_buffer.h"

#define SPI_FRAME_SIZE 5

/**
 * @brief SPI帧格式（来自主机）
 */
typedef struct {
    uint8_t id;         /* Frame ID / 序列号低字节 */
    uint8_t ack;        /* Acknowledge or extended sequence */
    uint8_t data_l;     /* ECG data low byte */
    uint8_t data_h;     /* ECG data high byte */
    uint8_t type;       /* Frame type / status */
} spi_frame_t;

/**
 * @brief SPI通信初始化（线程接收模式）
 * 
 * 功能：
 * - 配置NRF5340 SPI2为Slave模式
 * - 创建专用接收线程
 * - 自动启动连续接收
 * 
 * @param buffer 外部传入的ECG缓冲队列指针
 * @return 0成功，<0失败
 */
int spi_comm_init_async(ecg_buffer_t *buffer);

/**
 * @brief 获取SPI统计信息
 */
typedef struct {
    uint32_t frames_received;   /* 接收帧数 */
    uint32_t crc_errors;        /* CRC错误数 */
    uint32_t buffer_overruns;   /* 缓冲溢出数 */
    uint32_t seq_gaps;          /* 序列号中断数 */
} spi_stats_t;

spi_stats_t spi_comm_get_stats(void);

#endif /* SPI_COMM_H */
```

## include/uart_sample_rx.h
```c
#ifndef UART_SAMPLE_RX_H
#define UART_SAMPLE_RX_H

#include <stdbool.h>
#include <stdint.h>
#include "ecg_buffer.h"

#define UART_SAMPLE_FRAME_TYPE_DATASET 0xA1
#define UART_SAMPLE_MAX_WINDOW_SAMPLES 12000

typedef struct {
    uint8_t frame_type;
    uint16_t sample_count;
    uint16_t file_id;
    uint32_t rx_timestamp_ms;
} uart_window_header_t;

typedef struct {
    uint32_t bytes_received;
    uint32_t samples_received;
    uint32_t parse_errors;
    uint32_t buffer_overruns;
    int16_t last_sample;
    uint32_t last_seq;
    uint8_t has_sample;
} uart_sample_rx_stats_t;

int uart_sample_rx_init_async(ecg_buffer_t *buffer);
uart_sample_rx_stats_t uart_sample_rx_get_stats(void);
bool uart_sample_rx_try_get_window_header(uart_window_header_t *header);

#endif /* UART_SAMPLE_RX_H */
```
